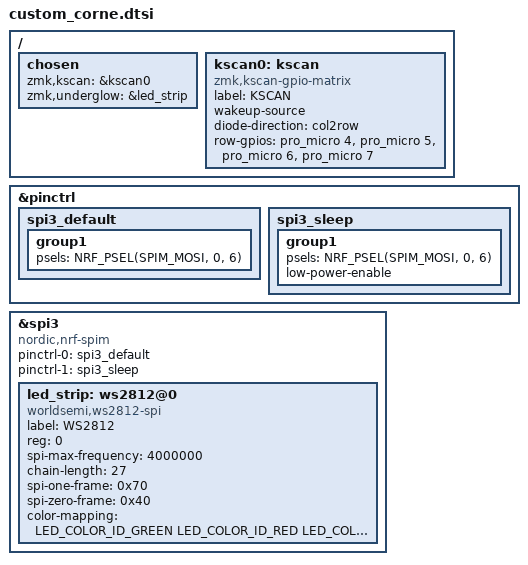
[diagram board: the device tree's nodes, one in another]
/*
 * Copyright (c) 2020 Pete Johanson
 *
 * SPDX-License-Identifier: MIT
 */
#include <dt-bindings/led/led.h>
#include <dt-bindings/zmk/matrix_transform.h>
/ {
	chosen {
		zmk,kscan = &kscan0;
		zmk,underglow = &led_strip;
	};

	 kscan0: kscan {
        compatible = "zmk,kscan-gpio-matrix";
        label = "KSCAN";
        wakeup-source;
        diode-direction = "col2row";
		row-gpios
			= <&pro_micro 4 (GPIO_ACTIVE_HIGH | GPIO_PULL_DOWN)>
			, <&pro_micro 5 (GPIO_ACTIVE_HIGH | GPIO_PULL_DOWN)>
			, <&pro_micro 6 (GPIO_ACTIVE_HIGH | GPIO_PULL_DOWN)>
			, <&pro_micro 7 (GPIO_ACTIVE_HIGH | GPIO_PULL_DOWN)>
			;
    };
};

// rgb,SPI
&pinctrl {
    spi3_default: spi3_default {
        group1 {
            psels = <NRF_PSEL(SPIM_MOSI, 0, 6)>;
        };
    };

    spi3_sleep: spi3_sleep {
        group1 {
            psels = <NRF_PSEL(SPIM_MOSI, 0, 6)>;
            low-power-enable;
		};
	};
};

&spi3 {
	compatible = "nordic,nrf-spim";
	status = "okay";

	pinctrl-0 = <&spi3_default>;
	pinctrl-1 = <&spi3_sleep>;
	pinctrl-names = "default", "sleep";


	led_strip: ws2812@0 {
		compatible = "worldsemi,ws2812-spi";
		label = "WS2812";

		/* SPI */
		reg = <0>; /* ignored, but necessary for SPI bindings */
		spi-max-frequency = <4000000>;

		/* WS2812 */
		chain-length = <27>; /* There are per-key RGB, but the first 6 are underglow */
		spi-one-frame = <0x70>;
		spi-zero-frame = <0x40>;
		color-mapping = <LED_COLOR_ID_GREEN LED_COLOR_ID_RED LED_COLOR_ID_BLUE>;
	};
};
